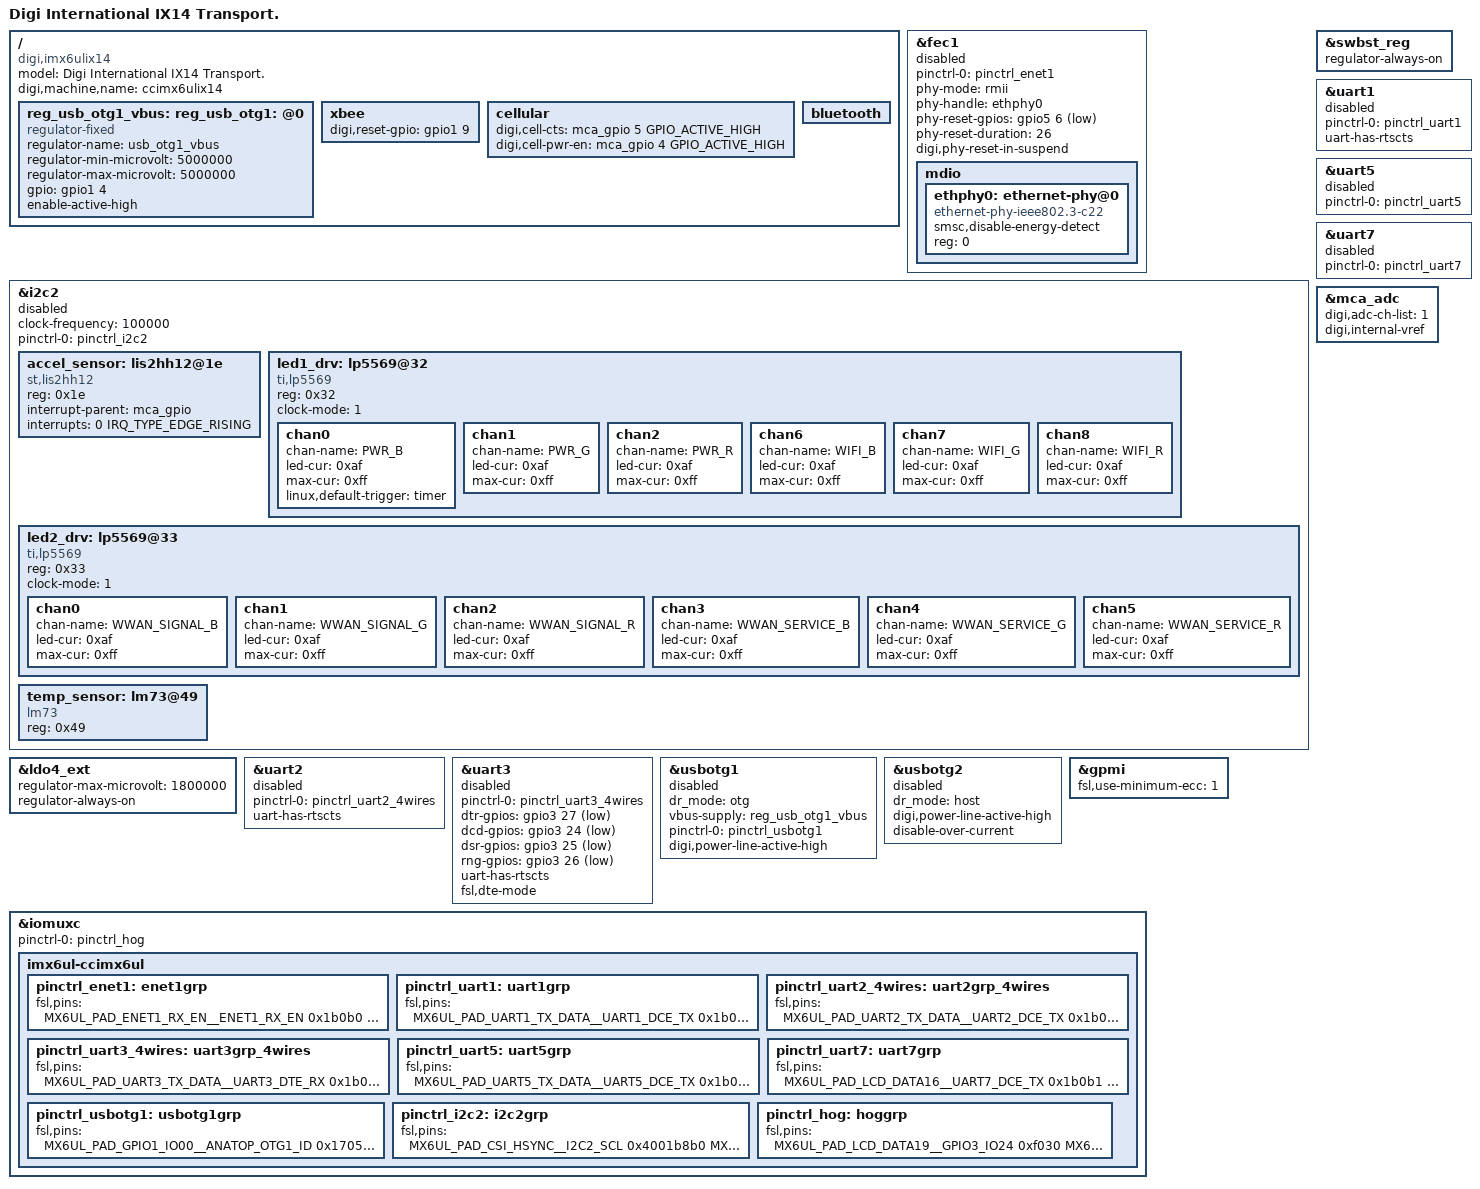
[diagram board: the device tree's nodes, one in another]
/*
 * Copyright 2018 Digi International, Inc.
 *
 * The code contained herein is licensed under the GNU General Public
 * License. You may obtain a copy of the GNU General Public License
 * Version 2 or later at the following locations:
 *
 * http://www.opensource.org/licenses/gpl-license.html
 * http://www.gnu.org/copyleft/gpl.html
 */

/ {
	model = "Digi International IX14 Transport.";
	compatible = "digi,imx6ulix14", "digi,ccimx6ulsbc", "digi,ccimx6ul", "fsl,imx6ul";
	digi,machine,name = "ccimx6ulix14";

	reg_usb_otg1_vbus: reg_usb_otg1:@0 {
		compatible = "regulator-fixed";
		regulator-name = "usb_otg1_vbus";
		regulator-min-microvolt = <5000000>;
		regulator-max-microvolt = <5000000>;
		gpio = <&gpio1 4 GPIO_ACTIVE_HIGH>;
		enable-active-high;
	};

	xbee {
		digi,reset-gpio = <&gpio1 9 GPIO_ACTIVE_HIGH>;
	};

	cellular {
		digi,cell-cts = <&mca_gpio 5 GPIO_ACTIVE_HIGH>;
		digi,cell-pwr-en = <&mca_gpio 4 GPIO_ACTIVE_HIGH>;
	};

	bluetooth {
		/* U-Boot will fill in the MAC address here */
	};
};

&fec1 {
	pinctrl-names = "default";
	pinctrl-0 = <&pinctrl_enet1>;
	phy-mode = "rmii";
	phy-handle = <&ethphy0>;
	phy-reset-gpios = <&gpio5 6 GPIO_ACTIVE_LOW>;
	phy-reset-duration = <26>;
	digi,phy-reset-in-suspend;
	status = "disabled";

	mdio {
		#address-cells = <1>;
		#size-cells = <0>;

		ethphy0: ethernet-phy@0 {
			compatible = "ethernet-phy-ieee802.3-c22";
			smsc,disable-energy-detect;
			reg = <0>;
		};
	};
};

&i2c2 {
	clock-frequency = <100000>;
	pinctrl-names = "default";
	pinctrl-0 = <&pinctrl_i2c2>;
	status = "disabled";

	accel_sensor: lis2hh12@1e {
		compatible = "st,lis2hh12";
		reg = <0x1e>;
		interrupt-parent = <&mca_gpio>;
		interrupts = <0 IRQ_TYPE_EDGE_RISING>;
	};

	led1_drv: lp5569@32 {
		compatible = "ti,lp5569";
		reg = <0x32>;
		clock-mode = /bits/ 8 <1>;
		chan0 {
			chan-name = "PWR_B";
			led-cur = /bits/ 8 <0xaf>;
			max-cur = /bits/ 8 <0xff>;
			linux,default-trigger = "timer";
		};
		chan1 {
			chan-name = "PWR_G";
			led-cur = /bits/ 8 <0xaf>;
			max-cur = /bits/ 8 <0xff>;
		};
		chan2 {
			chan-name = "PWR_R";
			led-cur = /bits/ 8 <0xaf>;
			max-cur = /bits/ 8 <0xff>;
		};
		/*
		 * This LED is not used in non-XBee non-GPS variants
		 *
		chan3 {
			chan-name = "TBD_B";
			led-cur = /bits/ 8 <0xaf>;
			max-cur = /bits/ 8 <0xff>;
		};
		chan4 {
			chan-name = "TBD_G";
			led-cur = /bits/ 8 <0xaf>;
			max-cur = /bits/ 8 <0xff>;
		};
		chan5 {
			chan-name = "TBD_R";
			led-cur = /bits/ 8 <0xaf>;
			max-cur = /bits/ 8 <0xff>;
		};
		*/
		chan6 {
			chan-name = "WIFI_B";
			led-cur = /bits/ 8 <0xaf>;
			max-cur = /bits/ 8 <0xff>;
		};
		chan7 {
			chan-name = "WIFI_G";
			led-cur = /bits/ 8 <0xaf>;
			max-cur = /bits/ 8 <0xff>;
		};
		chan8 {
			chan-name = "WIFI_R";
			led-cur = /bits/ 8 <0xaf>;
			max-cur = /bits/ 8 <0xff>;
		};
	};

	led2_drv: lp5569@33 {
		compatible = "ti,lp5569";
		reg = <0x33>;
		clock-mode = /bits/ 8 <1>;
		chan0 {
			chan-name = "WWAN_SIGNAL_B";
			led-cur = /bits/ 8 <0xaf>;
			max-cur = /bits/ 8 <0xff>;
		};
		chan1 {
			chan-name = "WWAN_SIGNAL_G";
			led-cur = /bits/ 8 <0xaf>;
			max-cur = /bits/ 8 <0xff>;
		};
		chan2 {
			chan-name = "WWAN_SIGNAL_R";
			led-cur = /bits/ 8 <0xaf>;
			max-cur = /bits/ 8 <0xff>;
		};
		chan3 {
			chan-name = "WWAN_SERVICE_B";
			led-cur = /bits/ 8 <0xaf>;
			max-cur = /bits/ 8 <0xff>;
		};
		chan4 {
			chan-name = "WWAN_SERVICE_G";
			led-cur = /bits/ 8 <0xaf>;
			max-cur = /bits/ 8 <0xff>;
		};
		chan5 {
			chan-name = "WWAN_SERVICE_R";
			led-cur = /bits/ 8 <0xaf>;
			max-cur = /bits/ 8 <0xff>;
		};
	};

	temp_sensor: lm73@49 {
		compatible = "lm73";
		reg = <0x49>;
	};
};

/* Powers LED driver with 1.8V */
&ldo4_ext {
	regulator-max-microvolt = <1800000>;
	regulator-always-on;
};

/* Powers the cellular modem */
&swbst_reg {
        regulator-always-on;
};

/* UART1 (Bluetooth) */
&uart1 {
	pinctrl-names = "default";
	pinctrl-0 = <&pinctrl_uart1>;
	uart-has-rtscts;
	status = "disabled";
};

/* UART2 (XBee) */
&uart2 {
	pinctrl-names = "default";
	pinctrl-0 = <&pinctrl_uart2_4wires>;
	uart-has-rtscts;
	status = "disabled";
};

/* UART3 */
&uart3 {
	pinctrl-names = "default";
	pinctrl-0 = <&pinctrl_uart3_4wires>;
	dtr-gpios = <&gpio3 27 GPIO_ACTIVE_LOW>;
	dcd-gpios = <&gpio3 24 GPIO_ACTIVE_LOW>;
	dsr-gpios = <&gpio3 25 GPIO_ACTIVE_LOW>;
	rng-gpios = <&gpio3 26 GPIO_ACTIVE_LOW>;
	uart-has-rtscts;
	fsl,dte-mode;
	status = "disabled";
};

/* UART5 (Console) */
&uart5 {
	pinctrl-names = "default";
	pinctrl-0 = <&pinctrl_uart5>;
	status = "disabled";
};

/* UART7 (GPS) */
&uart7 {
	pinctrl-names = "default";
	pinctrl-0 = <&pinctrl_uart7>;
	status = "disabled";
};

&usbotg1 {
	dr_mode = "otg";
	vbus-supply = <&reg_usb_otg1_vbus>;
	pinctrl-0 = <&pinctrl_usbotg1>;
	digi,power-line-active-high;
	status = "disabled";
};

&usbotg2 {
	dr_mode = "host";
	digi,power-line-active-high;
	disable-over-current;
	status = "disabled";
};

&gpmi {
	fsl,use-minimum-ecc = <1>;
};

&mca_adc {
	/* VIN MEASURE */
	digi,adc-ch-list = <1>;
	digi,internal-vref;
};

&iomuxc {
	pinctrl-names = "default";
	pinctrl-0 = <&pinctrl_hog>;

	imx6ul-ccimx6ul {
		pinctrl_enet1: enet1grp {
			fsl,pins = <
				MX6UL_PAD_ENET1_RX_EN__ENET1_RX_EN	0x1b0b0
				MX6UL_PAD_ENET1_RX_ER__ENET1_RX_ER	0x1b0b0
				MX6UL_PAD_ENET1_RX_DATA0__ENET1_RDATA00	0x1b0b0
				MX6UL_PAD_ENET1_RX_DATA1__ENET1_RDATA01	0x1b0b0
				MX6UL_PAD_ENET1_TX_EN__ENET1_TX_EN	0x1b0b0
				MX6UL_PAD_ENET1_TX_DATA0__ENET1_TDATA00	0x1b0b0
				MX6UL_PAD_ENET1_TX_DATA1__ENET1_TDATA01	0x1b0b0
				MX6UL_PAD_ENET1_TX_CLK__ENET1_REF_CLK1	0x40017051
				/* ENET_POWER */
				MX6UL_PAD_SNVS_TAMPER8__GPIO5_IO08 0x1b0b0
			>;
		};

		pinctrl_uart1: uart1grp {
			fsl,pins = <
				MX6UL_PAD_UART1_TX_DATA__UART1_DCE_TX	0x1b0b1
				MX6UL_PAD_UART1_RX_DATA__UART1_DCE_RX	0x1b0b1
				MX6UL_PAD_UART1_RTS_B__UART1_DCE_RTS	0x1b0b1
				MX6UL_PAD_UART1_CTS_B__UART1_DCE_CTS	0x1b0b1
			>;
		};

		pinctrl_uart2_4wires: uart2grp_4wires {
			fsl,pins = <
				MX6UL_PAD_UART2_TX_DATA__UART2_DCE_TX	0x1b0b1
				MX6UL_PAD_UART2_RX_DATA__UART2_DCE_RX	0x1b0b1
				MX6UL_PAD_UART2_CTS_B__UART2_DCE_CTS	0x1b0b1
				MX6UL_PAD_UART2_RTS_B__UART2_DCE_RTS	0x1b0b1
				/* Power-enable line */
				MX6UL_PAD_SNVS_TAMPER1__GPIO5_IO01	0xb0
			>;
		};

		pinctrl_uart3_4wires: uart3grp_4wires {
			fsl,pins = <
				MX6UL_PAD_UART3_TX_DATA__UART3_DTE_RX	0x1b0b1
				MX6UL_PAD_UART3_RX_DATA__UART3_DTE_TX	0x1b0b1
				MX6UL_PAD_UART3_CTS_B__UART3_DTE_RTS	0x1b0b1
				MX6UL_PAD_UART3_RTS_B__UART3_DTE_CTS	0x1b0b1
				/* Power-enable line */
				MX6UL_PAD_CSI_DATA00__GPIO4_IO21	0xb0
			>;
		};

		pinctrl_uart5: uart5grp {
			fsl,pins = <
				MX6UL_PAD_UART5_TX_DATA__UART5_DCE_TX	0x1b0b1
				MX6UL_PAD_UART5_RX_DATA__UART5_DCE_RX	0x1b0b1
			>;
		};

		pinctrl_uart7: uart7grp {
			fsl,pins = <
				MX6UL_PAD_LCD_DATA16__UART7_DCE_TX	0x1b0b1
				MX6UL_PAD_LCD_DATA17__UART7_DCE_RX	0x1b0b1
				/* Power-enable line */
				MX6UL_PAD_LCD_ENABLE__GPIO3_IO01	0xb0
			>;
		};

		pinctrl_usbotg1: usbotg1grp {
			fsl,pins = <
				MX6UL_PAD_GPIO1_IO00__ANATOP_OTG1_ID	0x17059
				/* USBOTG1 PWR */
				MX6UL_PAD_GPIO1_IO01__USB_OTG1_OC	0x17059
			>;
		};

		pinctrl_i2c2: i2c2grp {
			fsl,pins = <
				MX6UL_PAD_CSI_HSYNC__I2C2_SCL 0x4001b8b0
				MX6UL_PAD_CSI_VSYNC__I2C2_SDA 0x4001b8b0
			>;
		};

		/* General purpose pinctrl */
		pinctrl_hog: hoggrp {
			fsl,pins = <
				/* GPIO3_IO24 UART3_DCD */
				MX6UL_PAD_LCD_DATA19__GPIO3_IO24 0xf030
				/* GPIO3_IO24 UART3_DSR */
				MX6UL_PAD_LCD_DATA20__GPIO3_IO25 0xf030
				/* GPIO3_IO24 UART3_RI */
				MX6UL_PAD_LCD_DATA21__GPIO3_IO26 0xf030
				/* GPIO3_IO24 UART3_DTR */
				MX6UL_PAD_LCD_DATA22__GPIO3_IO27 0xf030
				/* XBEE_DTR */
				MX6UL_PAD_CSI_DATA01__GPIO4_IO22 0x1b0b1
				/* CELL_SW_READY */
				MX6UL_PAD_SNVS_TAMPER2__GPIO5_IO02 0x1b0b1
				/* CELL_PWRMON */
				MX6UL_PAD_CSI_DATA03__GPIO4_IO24 0x1a0b1
				/* CELL_IGN */
				MX6UL_PAD_LCD_CLK__GPIO3_IO00 0x1b0b1
				/* CELL_EMERG_OFF */
				MX6UL_PAD_CSI_DATA05__GPIO4_IO26 0x1b0b1
				/* SIM_SWITCH */
				MX6UL_PAD_SNVS_TAMPER5__GPIO5_IO05 0x1b0b1
				/* SIM_1_DETECT */
				MX6UL_PAD_LCD_VSYNC__GPIO3_IO03 0x1b0b1
				/* SIM_2_DETECT */
				MX6UL_PAD_LCD_HSYNC__GPIO3_IO02 0x1b0b1
				/* GPS_RST */
				MX6UL_PAD_GPIO1_IO05__GPIO1_IO05 0x1b0b1
				/* PUSH_BUTTON */
				MX6UL_PAD_SNVS_TAMPER7__GPIO5_IO07 0x1b0b1
				/* LED_EN_PWM */
				MX6UL_PAD_CSI_DATA02__GPIO4_IO23 0x1b0b1
				/* SECURITY_KEY (with internal pull down) */
				MX6UL_PAD_CSI_DATA04__GPIO4_IO25 0x130b1
			>;
		};
	};
};
